AUTOSAR XML (schema 4-2-2)
package /Components
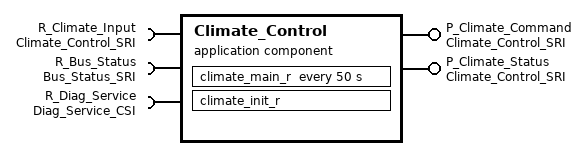
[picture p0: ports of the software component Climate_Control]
  application sw component type Climate_Control
    provide port P_Climate_Command: provided-interface=Climate_Control_SRI
    provide port P_Climate_Status: provided-interface=Climate_Control_SRI
    require port R_Climate_Input: required-interface=Climate_Control_SRI
    require port R_Bus_Status: required-interface=Bus_Status_SRI
    require port R_Diag_Service: required-interface=Diag_Service_CSI
    behavior Climate_Control_InternalBehavior
      init event Climate_Init: start-on-event=climate_init_r
      timing event Climate_Main_Cycle: start-on-event=climate_main_r, period=50
      runnable climate_init_r
        data-receive-point-by-values:
          access rx_bus_online_init: accessed-variable=R_Bus_Status.bus_online
        data-send-points:
          access tx_initial_ac_status: accessed-variable=P_Climate_Status.ac_status
        parameter access param_read_bus_error_count_init: accessed-parameter=R_Bus_Status.bus_error_count
        parameter access param_read_bus_load_init: accessed-parameter=R_Bus_Status.bus_load
        sync call scp_get_update_status_init: operation=R_Diag_Service.GetUpdateStatus, timeout=1000
      runnable climate_main_r: minimum-start-interval=50
        data-receive-point-by-values:
          6 x access:
            rx_hvac_target_temp: accessed-variable=R_Climate_Input.hvac_target_temp
            rx_fan_speed_cmd: accessed-variable=R_Climate_Input.fan_speed_cmd
            rx_cabin_temp_feedback: accessed-variable=R_Climate_Input.cabin_temp_feedback
            rx_bus_online: accessed-variable=R_Bus_Status.bus_online
            rx_bus_error_count: accessed-variable=R_Bus_Status.bus_error_count
            rx_bus_load: accessed-variable=R_Bus_Status.bus_load
        data-send-points:
          access tx_ac_on_cmd: accessed-variable=P_Climate_Command.ac_on_cmd
          access tx_fan_speed_cmd: accessed-variable=P_Climate_Command.fan_speed_cmd
          access tx_ac_status: accessed-variable=P_Climate_Status.ac_status
        parameter access param_read_bus_load_main: accessed-parameter=R_Bus_Status.bus_load
        sync call scp_get_update_status_main: operation=R_Diag_Service.GetUpdateStatus, timeout=1000
